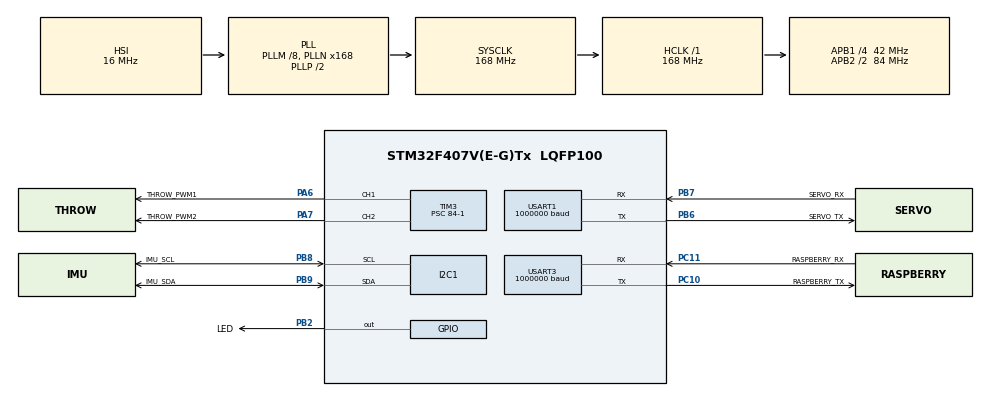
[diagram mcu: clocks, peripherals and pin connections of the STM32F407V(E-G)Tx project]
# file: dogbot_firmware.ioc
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Dma.I2C1_RX.2.Direction=DMA_PERIPH_TO_MEMORY
Dma.I2C1_RX.2.FIFOMode=DMA_FIFOMODE_DISABLE
Dma.I2C1_RX.2.Instance=DMA1_Stream0
Dma.I2C1_RX.2.MemDataAlignment=DMA_MDATAALIGN_BYTE
Dma.I2C1_RX.2.MemInc=DMA_MINC_ENABLE
Dma.I2C1_RX.2.Mode=DMA_NORMAL
Dma.I2C1_RX.2.PeriphDataAlignment=DMA_PDATAALIGN_BYTE
Dma.I2C1_RX.2.PeriphInc=DMA_PINC_DISABLE
Dma.I2C1_RX.2.Priority=DMA_PRIORITY_LOW
Dma.I2C1_TX.3.Direction=DMA_MEMORY_TO_PERIPH
Dma.I2C1_TX.3.FIFOMode=DMA_FIFOMODE_DISABLE
Dma.I2C1_TX.3.Instance=DMA1_Stream6
Dma.I2C1_TX.3.MemDataAlignment=DMA_MDATAALIGN_BYTE
Dma.I2C1_TX.3.MemInc=DMA_MINC_ENABLE
Dma.I2C1_TX.3.Mode=DMA_NORMAL
Dma.I2C1_TX.3.PeriphDataAlignment=DMA_PDATAALIGN_BYTE
Dma.I2C1_TX.3.PeriphInc=DMA_PINC_DISABLE
Dma.I2C1_TX.3.Priority=DMA_PRIORITY_LOW
Dma.Request0=USART1_TX
Dma.Request1=USART3_TX
Dma.Request2=I2C1_RX
Dma.Request3=I2C1_TX
Dma.USART1_TX.0.Direction=DMA_MEMORY_TO_PERIPH
Dma.USART1_TX.0.FIFOMode=DMA_FIFOMODE_DISABLE
Dma.USART1_TX.0.Instance=DMA2_Stream7
Dma.USART1_TX.0.MemDataAlignment=DMA_MDATAALIGN_BYTE
Dma.USART1_TX.0.MemInc=DMA_MINC_ENABLE
Dma.USART1_TX.0.Mode=DMA_NORMAL
Dma.USART1_TX.0.PeriphDataAlignment=DMA_PDATAALIGN_BYTE
Dma.USART1_TX.0.PeriphInc=DMA_PINC_DISABLE
Dma.USART1_TX.0.Priority=DMA_PRIORITY_LOW
Dma.USART3_TX.1.Direction=DMA_MEMORY_TO_PERIPH
Dma.USART3_TX.1.FIFOMode=DMA_FIFOMODE_DISABLE
Dma.USART3_TX.1.Instance=DMA1_Stream3
Dma.USART3_TX.1.MemDataAlignment=DMA_MDATAALIGN_BYTE
Dma.USART3_TX.1.MemInc=DMA_MINC_ENABLE
Dma.USART3_TX.1.Mode=DMA_NORMAL
Dma.USART3_TX.1.PeriphDataAlignment=DMA_PDATAALIGN_BYTE
Dma.USART3_TX.1.PeriphInc=DMA_PINC_DISABLE
Dma.USART3_TX.1.Priority=DMA_PRIORITY_LOW
I2C1.I2C_Mode=I2C_Fast
Mcu.Family=STM32F4
Mcu.Name=STM32F407V(E-G)Tx
Mcu.Package=LQFP100
NVIC.DMA1_Stream0_IRQn=true\:2\:0\:true\:false\:true\:false\:true\:true
NVIC.DMA1_Stream3_IRQn=true\:4\:0\:true\:false\:true\:false\:true\:true
NVIC.DMA1_Stream6_IRQn=true\:2\:0\:true\:false\:true\:false\:true\:true
NVIC.DMA2_Stream7_IRQn=true\:4\:0\:true\:false\:true\:false\:true\:true
NVIC.I2C1_ER_IRQn=true\:3\:0\:true\:false\:true\:true\:true\:true
NVIC.I2C1_EV_IRQn=true\:3\:0\:true\:false\:true\:true\:true\:true
NVIC.PriorityGroup=NVIC_PRIORITYGROUP_4
NVIC.USART1_IRQn=true\:0\:0\:false\:false\:true\:true\:true\:true
NVIC.USART3_IRQn=true\:0\:0\:false\:false\:true\:true\:true\:true
PA6.GPIO_Label=THROW_PWM1
PA6.Signal=S_TIM3_CH1
PA7.GPIO_Label=THROW_PWM2
PA7.Signal=S_TIM3_CH2
PB2.GPIO_Label=LED
PB2.Signal=GPIO_Output
PB6.GPIO_Label=SERVO_TX
PB6.Mode=Asynchronous
PB6.Signal=USART1_TX
PB7.GPIO_Label=SERVO_RX
PB7.Mode=Asynchronous
PB7.Signal=USART1_RX
PB8.GPIO_Label=IMU_SCL
PB8.Mode=I2C
PB8.Signal=I2C1_SCL
PB9.GPIO_Label=IMU_SDA
PB9.Mode=I2C
PB9.Signal=I2C1_SDA
PC10.GPIO_Label=RASPBERRY_TX
PC10.Mode=Asynchronous
PC10.Signal=USART3_TX
PC11.GPIO_Label=RASPBERRY_RX
PC11.Mode=Asynchronous
PC11.Signal=USART3_RX
ProjectManager.HeapSize=0x200
ProjectManager.StackSize=0x400
ProjectManager.TargetToolchain=CMake
RCC.48MHZClocksFreq_Value=84000000
RCC.AHBFreq_Value=168000000
RCC.APB1CLKDivider=RCC_HCLK_DIV4
RCC.APB1Freq_Value=42000000
RCC.APB1TimFreq_Value=84000000
RCC.APB2CLKDivider=RCC_HCLK_DIV2
RCC.APB2Freq_Value=84000000
RCC.APB2TimFreq_Value=168000000
RCC.CortexFreq_Value=168000000
RCC.HCLKFreq_Value=168000000
RCC.HSE_VALUE=25000000
RCC.HSI_VALUE=16000000
RCC.LSE_VALUE=32768
RCC.PLLM=8
RCC.PLLN=168
RCC.SYSCLKFreq_VALUE=168000000
RCC.SYSCLKSource=RCC_SYSCLKSOURCE_PLLCLK
RCC.VCOOutputFreq_Value=336000000
SH.S_TIM3_CH1.0=TIM3_CH1,PWM Generation1 CH1
SH.S_TIM3_CH2.0=TIM3_CH2,PWM Generation2 CH2
TIM3.AutoReloadPreload=TIM_AUTORELOAD_PRELOAD_ENABLE
TIM3.Channel-PWM\ Generation1\ CH1=TIM_CHANNEL_1
TIM3.Channel-PWM\ Generation2\ CH2=TIM_CHANNEL_2
TIM3.Period=20000-1
TIM3.Prescaler=84-1
TIM3.Pulse-PWM\ Generation1\ CH1=500
TIM3.Pulse-PWM\ Generation2\ CH2=500
USART1.BaudRate=1000000
USART1.VirtualMode=VM_ASYNC
USART3.BaudRate=1000000
USART3.VirtualMode=VM_ASYNC
VP_TIM3_VS_ClockSourceINT.Mode=Internal
board=custom

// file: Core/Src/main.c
/* USER CODE BEGIN Header */
/**
  ******************************************************************************
  * @file           : main.c
  * @brief          : Main program body
  ******************************************************************************
  * @attention
  *
  * Copyright (c) 2026 STMicroelectronics.
  * All rights reserved.
  *
  * This software is licensed under terms that can be found in the LICENSE file
  * in the root directory of this software component.
  * If no LICENSE file comes with this software, it is provided AS-IS.
  *
  ******************************************************************************
  */
/* USER CODE END Header */
#include "main.h"
#include "dma.h"
#include "i2c.h"
#include "tim.h"
#include "usart.h"
#include "gpio.h"

/* USER CODE BEGIN Includes */
#include "app.h"
/* USER CODE END Includes */

void SystemClock_Config(void);

int main(void)
{

  /* MCU Configuration--------------------------------------------------------*/

  /* Reset of all peripherals, Initializes the Flash interface and the Systick. */
  HAL_Init();

  /* Configure the system clock */
  SystemClock_Config();

  /* Initialize all configured peripherals */
  MX_GPIO_Init();
  MX_DMA_Init();
  MX_USART1_UART_Init();
  MX_USART3_UART_Init();
  MX_I2C1_Init();
  MX_TIM3_Init();
  /* USER CODE BEGIN 2 */
  HAL_TIM_PWM_Start(&htim3, TIM_CHANNEL_1);
  HAL_TIM_PWM_Start(&htim3, TIM_CHANNEL_2);
  app_init();
  /* USER CODE END 2 */

  /* Infinite loop */
  while (1)
  {

    /* USER CODE BEGIN 3 */
    app_loop();
  }
  /* USER CODE END 3 */
}

void SystemClock_Config(void)
{
  RCC_OscInitTypeDef RCC_OscInitStruct = {0};
  RCC_ClkInitTypeDef RCC_ClkInitStruct = {0};

  /** Configure the main internal regulator output voltage
  */
  __HAL_RCC_PWR_CLK_ENABLE();
  __HAL_PWR_VOLTAGESCALING_CONFIG(PWR_REGULATOR_VOLTAGE_SCALE1);

  /** Initializes the RCC Oscillators according to the specified parameters
  * in the RCC_OscInitTypeDef structure.
  */
  RCC_OscInitStruct.OscillatorType = RCC_OSCILLATORTYPE_HSI;
  RCC_OscInitStruct.HSIState = RCC_HSI_ON;
  RCC_OscInitStruct.HSICalibrationValue = RCC_HSICALIBRATION_DEFAULT;
  RCC_OscInitStruct.PLL.PLLState = RCC_PLL_ON;
  RCC_OscInitStruct.PLL.PLLSource = RCC_PLLSOURCE_HSI;
  RCC_OscInitStruct.PLL.PLLM = 8;
  RCC_OscInitStruct.PLL.PLLN = 168;
  RCC_OscInitStruct.PLL.PLLP = RCC_PLLP_DIV2;
  RCC_OscInitStruct.PLL.PLLQ = 4;
  if (HAL_RCC_OscConfig(&RCC_OscInitStruct) != HAL_OK)
  {
    Error_Handler();
  }

  /** Initializes the CPU, AHB and APB buses clocks
  */
  RCC_ClkInitStruct.ClockType = RCC_CLOCKTYPE_HCLK|RCC_CLOCKTYPE_SYSCLK
                              |RCC_CLOCKTYPE_PCLK1|RCC_CLOCKTYPE_PCLK2;
  RCC_ClkInitStruct.SYSCLKSource = RCC_SYSCLKSOURCE_PLLCLK;
  RCC_ClkInitStruct.AHBCLKDivider = RCC_SYSCLK_DIV1;
  RCC_ClkInitStruct.APB1CLKDivider = RCC_HCLK_DIV4;
  RCC_ClkInitStruct.APB2CLKDivider = RCC_HCLK_DIV2;

  if (HAL_RCC_ClockConfig(&RCC_ClkInitStruct, FLASH_LATENCY_5) != HAL_OK)
  {
    Error_Handler();
  }
}

void Error_Handler(void)
{
  __disable_irq();
  while (1)
  {
  }
}
